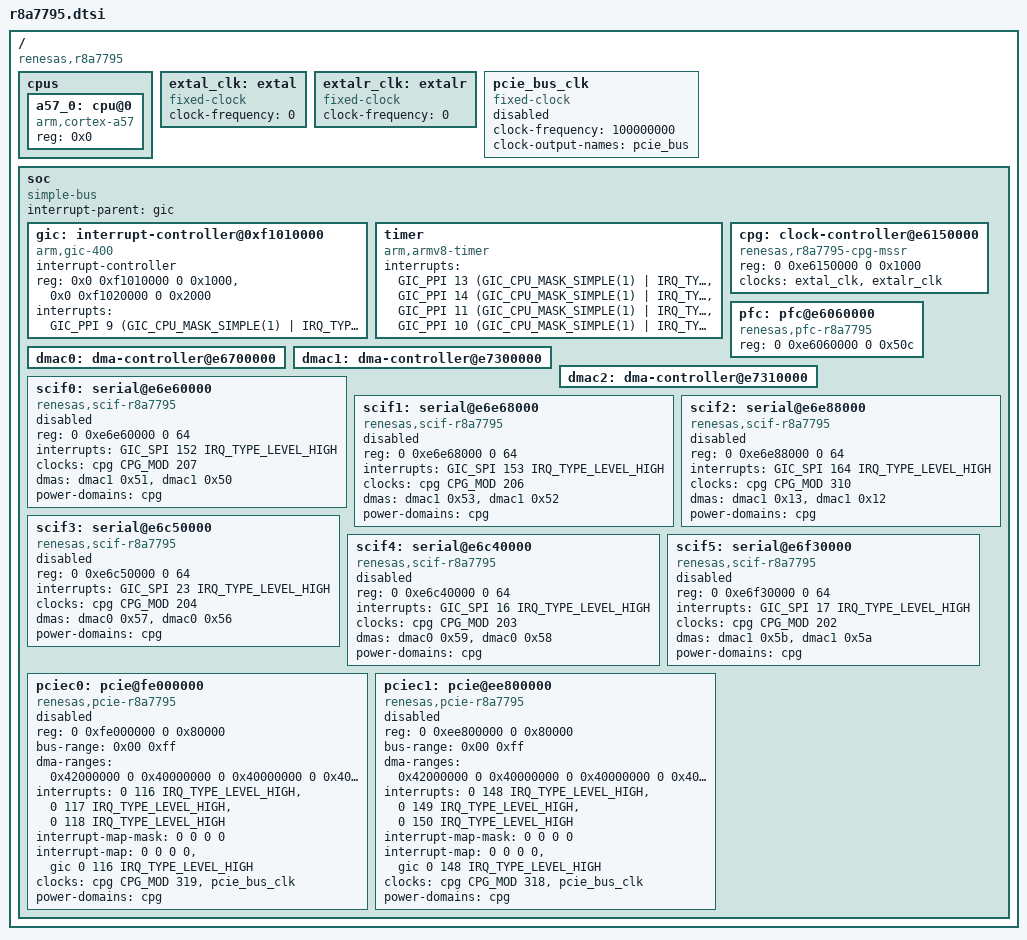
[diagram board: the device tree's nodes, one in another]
/*
 * Device Tree Source for the r8a7795 SoC
 *
 * Copyright (C) 2015 Renesas Electronics Corp.
 *
 * This file is licensed under the terms of the GNU General Public License
 * version 2.  This program is licensed "as is" without any warranty of any
 * kind, whether express or implied.
 */

#include <dt-bindings/clock/r8a7795-cpg-mssr.h>
#include <dt-bindings/interrupt-controller/arm-gic.h>

/ {
	compatible = "renesas,r8a7795";
	#address-cells = <2>;
	#size-cells = <2>;

	cpus {
		#address-cells = <1>;
		#size-cells = <0>;

		/* 1core only at this point */
		a57_0: cpu@0 {
			compatible = "arm,cortex-a57", "arm,armv8";
			reg = <0x0>;
			device_type = "cpu";
		};
	};

	extal_clk: extal {
		compatible = "fixed-clock";
		#clock-cells = <0>;
		clock-frequency = <0>;
	};

	extalr_clk: extalr {
		compatible = "fixed-clock";
		#clock-cells = <0>;
		/* This value must be overridden by the board */
		clock-frequency = <0>;
	};

	/* External PCIe clock - can be overridden by the board */
	pcie_bus_clk: pcie_bus_clk {
		compatible = "fixed-clock";
		#clock-cells = <0>;
		clock-frequency = <100000000>;
		clock-output-names = "pcie_bus";
		status = "disabled";
	};

	soc {
		compatible = "simple-bus";
		interrupt-parent = <&gic>;
		#address-cells = <2>;
		#size-cells = <2>;
		ranges;

		gic: interrupt-controller@0xf1010000 {
			compatible = "arm,gic-400";
			#interrupt-cells = <3>;
			#address-cells = <0>;
			interrupt-controller;
			reg = <0x0 0xf1010000 0 0x1000>,
			      <0x0 0xf1020000 0 0x2000>;
			interrupts = <GIC_PPI 9
					(GIC_CPU_MASK_SIMPLE(1) | IRQ_TYPE_LEVEL_HIGH)>;
		};

		timer {
			compatible = "arm,armv8-timer";
			interrupts = <GIC_PPI 13
					(GIC_CPU_MASK_SIMPLE(1) | IRQ_TYPE_LEVEL_LOW)>,
				     <GIC_PPI 14
					(GIC_CPU_MASK_SIMPLE(1) | IRQ_TYPE_LEVEL_LOW)>,
				     <GIC_PPI 11
					(GIC_CPU_MASK_SIMPLE(1) | IRQ_TYPE_LEVEL_LOW)>,
				     <GIC_PPI 10
					(GIC_CPU_MASK_SIMPLE(1) | IRQ_TYPE_LEVEL_LOW)>;
		};

		cpg: clock-controller@e6150000 {
			compatible = "renesas,r8a7795-cpg-mssr";
			reg = <0 0xe6150000 0 0x1000>;
			clocks = <&extal_clk>, <&extalr_clk>;
			clock-names = "extal", "extalr";
			#clock-cells = <2>;
			#power-domain-cells = <0>;
		};

		pfc: pfc@e6060000 {
			compatible = "renesas,pfc-r8a7795";
			reg = <0 0xe6060000 0 0x50c>;
		};

		dmac0: dma-controller@e6700000 {
			/* Empty node for now */
		};

		dmac1: dma-controller@e7300000 {
			/* Empty node for now */
		};

		dmac2: dma-controller@e7310000 {
			/* Empty node for now */
		};

		scif0: serial@e6e60000 {
			compatible = "renesas,scif-r8a7795", "renesas,scif";
			reg = <0 0xe6e60000 0 64>;
			interrupts = <GIC_SPI 152 IRQ_TYPE_LEVEL_HIGH>;
			clocks = <&cpg CPG_MOD 207>;
			clock-names = "sci_ick";
			dmas = <&dmac1 0x51>, <&dmac1 0x50>;
			dma-names = "tx", "rx";
			power-domains = <&cpg>;
			status = "disabled";
		};

		scif1: serial@e6e68000 {
			compatible = "renesas,scif-r8a7795", "renesas,scif";
			reg = <0 0xe6e68000 0 64>;
			interrupts = <GIC_SPI 153 IRQ_TYPE_LEVEL_HIGH>;
			clocks = <&cpg CPG_MOD 206>;
			clock-names = "sci_ick";
			dmas = <&dmac1 0x53>, <&dmac1 0x52>;
			dma-names = "tx", "rx";
			power-domains = <&cpg>;
			status = "disabled";
		};

		scif2: serial@e6e88000 {
			compatible = "renesas,scif-r8a7795", "renesas,scif";
			reg = <0 0xe6e88000 0 64>;
			interrupts = <GIC_SPI 164 IRQ_TYPE_LEVEL_HIGH>;
			clocks = <&cpg CPG_MOD 310>;
			clock-names = "sci_ick";
			dmas = <&dmac1 0x13>, <&dmac1 0x12>;
			dma-names = "tx", "rx";
			power-domains = <&cpg>;
			status = "disabled";
		};

		scif3: serial@e6c50000 {
			compatible = "renesas,scif-r8a7795", "renesas,scif";
			reg = <0 0xe6c50000 0 64>;
			interrupts = <GIC_SPI 23 IRQ_TYPE_LEVEL_HIGH>;
			clocks = <&cpg CPG_MOD 204>;
			clock-names = "sci_ick";
			dmas = <&dmac0 0x57>, <&dmac0 0x56>;
			dma-names = "tx", "rx";
			power-domains = <&cpg>;
			status = "disabled";
		};

		scif4: serial@e6c40000 {
			compatible = "renesas,scif-r8a7795", "renesas,scif";
			reg = <0 0xe6c40000 0 64>;
			interrupts = <GIC_SPI 16 IRQ_TYPE_LEVEL_HIGH>;
			clocks = <&cpg CPG_MOD 203>;
			clock-names = "sci_ick";
			dmas = <&dmac0 0x59>, <&dmac0 0x58>;
			dma-names = "tx", "rx";
			power-domains = <&cpg>;
			status = "disabled";
		};

		scif5: serial@e6f30000 {
			compatible = "renesas,scif-r8a7795", "renesas,scif";
			reg = <0 0xe6f30000 0 64>;
			interrupts = <GIC_SPI 17 IRQ_TYPE_LEVEL_HIGH>;
			clocks = <&cpg CPG_MOD 202>;
			clock-names = "sci_ick";
			dmas = <&dmac1 0x5b>, <&dmac1 0x5a>;
			dma-names = "tx", "rx";
			power-domains = <&cpg>;
			status = "disabled";
		};

		pciec0: pcie@fe000000 {
			compatible = "renesas,pcie-r8a7795";
			reg = <0 0xfe000000 0 0x80000>;
			#address-cells = <3>;
			#size-cells = <2>;
			bus-range = <0x00 0xff>;
			device_type = "pci";
			ranges = <0x01000000 0 0x00000000 0 0xfe100000 0 0x00100000
				0x02000000 0 0xfe200000 0 0xfe200000 0 0x00200000
				0x02000000 0 0x30000000 0 0x30000000 0 0x08000000
				0x42000000 0 0x38000000 0 0x38000000 0 0x08000000>;
			/* Map all possible DDR as inbound ranges */
			dma-ranges = <0x42000000 0 0x40000000 0 0x40000000 0 0x40000000>;
			interrupts = <0 116 IRQ_TYPE_LEVEL_HIGH>,
				<0 117 IRQ_TYPE_LEVEL_HIGH>,
				<0 118 IRQ_TYPE_LEVEL_HIGH>;
			#interrupt-cells = <1>;
			interrupt-map-mask = <0 0 0 0>;
			interrupt-map = <0 0 0 0 &gic 0 116 IRQ_TYPE_LEVEL_HIGH>;
			clocks = <&cpg CPG_MOD 319>, <&pcie_bus_clk>;
			clock-names = "pcie", "pcie_bus";
			power-domains = <&cpg>;
			status = "disabled";
		};

		pciec1: pcie@ee800000 {
			compatible = "renesas,pcie-r8a7795";
			reg = <0 0xee800000 0 0x80000>;
			#address-cells = <3>;
			#size-cells = <2>;
			bus-range = <0x00 0xff>;
			device_type = "pci";
			ranges = <0x01000000 0 0x00000000 0 0xee900000 0 0x00100000
				0x02000000 0 0xeea00000 0 0xeea00000 0 0x00200000
				0x02000000 0 0xc0000000 0 0xc0000000 0 0x08000000
				0x42000000 0 0xc8000000 0 0xc8000000 0 0x08000000>;
			/* Map all possible DDR as inbound ranges */
			dma-ranges = <0x42000000 0 0x40000000 0 0x40000000 0 0x40000000>;
			interrupts = <0 148 IRQ_TYPE_LEVEL_HIGH>,
				<0 149 IRQ_TYPE_LEVEL_HIGH>,
				<0 150 IRQ_TYPE_LEVEL_HIGH>;
			#interrupt-cells = <1>;
			interrupt-map-mask = <0 0 0 0>;
			interrupt-map = <0 0 0 0 &gic 0 148 IRQ_TYPE_LEVEL_HIGH>;
			clocks = <&cpg CPG_MOD 318>, <&pcie_bus_clk>;
			clock-names = "pcie", "pcie_bus";
			power-domains = <&cpg>;
			status = "disabled";
		};
	};
};
